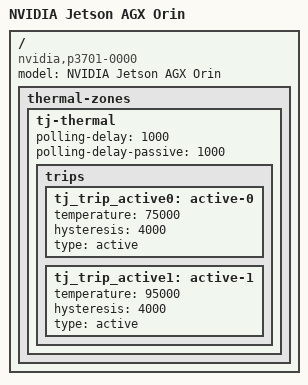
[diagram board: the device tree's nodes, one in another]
// SPDX-License-Identifier: GPL-2.0

#include "tegra234-p3701.dtsi"

/ {
	model = "NVIDIA Jetson AGX Orin";
	compatible = "nvidia,p3701-0000", "nvidia,tegra234";

	thermal-zones {
		tj-thermal {
			polling-delay = <1000>;
			polling-delay-passive = <1000>;
			status = "okay";

			trips {
				tj_trip_active0: active-0 {
					temperature = <75000>;
					hysteresis = <4000>;
					type = "active";
				};

				tj_trip_active1: active-1 {
					temperature = <95000>;
					hysteresis = <4000>;
					type = "active";
				};
			};
		};
	};
};
